# i2c_master_model: IP-XACT component
VLNV IcronTechnologies:IcronTechnologies:i2c_master_model:1.0

## Parameters
addr_width = 8
bus_width = 32

## Bus interfaces (logical=physical port)
default_map: slave AGNISYS:AGNISYS:APB:1.0, memory map i2c_mastermap
  pclk=pclk, presetn=presetn, psel=psel, penable=penable, pwrite=pwrite, pprot=pprot, pstrb=pstrb, pwdata=pwdata, paddr=paddr, pready=pready, prdata=prdata, pslverr=pslverr

## Ports
in pclk
in presetn
in psel
in penable
in pwrite
in pprot[2:0]
in pstrb[(bus_width div 8 )-1:0]
in pwdata[bus_width -1:0]
in paddr[addr_width -1:0]
out pready
out prdata[bus_width -1:0]
out pslverr
out i2c_master_regsversion_major_r[7:0]
out i2c_master_regsversion_minor_r[7:0]
out i2c_master_regsversion_patch_r[7:0]
out i2c_master_regsprescaler_enb
out i2c_master_regsprescaler_prescaler_r[15:0]
out i2c_master_regsfifo_enb
in i2c_master_regsfifo_fifo_af_in
in i2c_master_regsfifo_fifo_af_in_enb
in i2c_master_regsfifo_fifo_ae_in
in i2c_master_regsfifo_fifo_ae_in_enb
in i2c_master_regsfifo_fifo_full_in
in i2c_master_regsfifo_fifo_full_in_enb
in i2c_master_regsfifo_fifo_empty_in
in i2c_master_regsfifo_fifo_empty_in_enb
out i2c_master_regsfifo_fifo_aft_r[7:0]
out i2c_master_regsfifo_fifo_aet_r[7:0]
in i2c_master_regsfifo_fifo_depth_in[7:0]
in i2c_master_regsfifo_fifo_depth_in_enb
out i2c_master_regscontrol_enb
in i2c_master_regscontrol_error_in
in i2c_master_regscontrol_error_in_enb
in i2c_master_regscontrol_clock_stretch_active_in
in i2c_master_regscontrol_clock_stretch_active_in_enb
out i2c_master_regscontrol_force_sda_low_r
out i2c_master_regscontrol_slave_addr_r[6:0]
out i2c_master_regscontrol_read_byte_count_r[7:0]
out i2c_master_regscontrol_clear_r
out i2c_master_regscontrol_opmode_r[1:0]
out i2c_master_regscontrol_clock_stretch_en_r
out i2c_master_regscontrol_go_r
in i2c_master_regscontrol_go_hw_clear
out i2c_master_regswr_data_enb
out i2c_master_regswr_data_wr_data_r[7:0]
out i2c_master_regsregwr_data_wr_data_wr_pulse
in i2c_master_regsrd_data_rd_data_in[7:0]
in i2c_master_regsrd_data_rd_data_in_enb
out i2c_master_regsrd_data_rd_data_rd_pulse

## Address spaces and blocks
i2c_mastermap.i2c_master: base 0x000, range 0x100, width 32

## Registers
Registers are 32-bit, read-only, reset 0x0 unless marked. A register's access mark holds for its fields unless they carry their own. Offsets are from the block's base; lines under a group give offsets from that group; [hi:lo] are bit positions; {n}, {i} and the like mark numbered series; 'fields as' and 'values as' point back to an identical list; <NAME> marks a mode.

## i2c_mastermap.i2c_master — I2C Master
Base 0x00000000
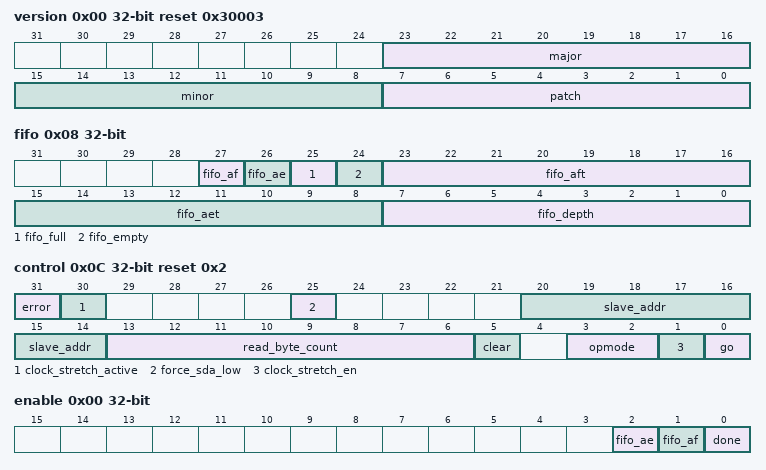
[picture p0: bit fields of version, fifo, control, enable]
0x00 version reset 0x30003
  [23:16] major — Major version
  [15:8] minor — Minor version
  [7:0] patch — Patch version
0x04 prescaler rw — I2C prescaler
  [15:0] prescaler — Prescaler reload value. The value defines the number of clocks in a quarter SCL period. E.g. for a 60MHz clock and a prescaler value of 15 a 1000 KHz SCL will be generated (60e6 * (1 / (15 * 4))).
0x08 fifo access per field — I2C FIFO control and status
  [27] fifo_af ro — FIFO almost full status field. A 1 indicates an almost full or full FIFO. This bit is set when there are between fifo_af_lvl and fifo_depth number of entries in the FIFO.
  [26] fifo_ae ro — FIFO almost empty status field. A 1 indicates an almost empty or empty FIFO. This bit is set when there are between 0 and fifo_ae_lvl number of entries in the FIFO.
  [25] fifo_full ro — FIFO full status field. A 1 indicates a full FIFO.
  [24] fifo_empty ro — FIFO empty status field. A 1 indicates an empty FIFO.
  [23:16] fifo_aft rw — FIFO almost full threshold
  [15:8] fifo_aet rw — FIFO almost empty threshold
  [7:0] fifo_depth ro — FIFO depth (always 1 byte wide)
0x0C control access per field reset 0x2 — I2C control
  [31] error ro — Error status field. A 1 indicates that a transaction error occurred. This could be due to a NAK or a read from the bus when the FIFO is full. This bit is sticky until the clear field is asserted or a new transaction is started.
  [30] clock_stretch_active ro — This status field indicates whether the I2C master is currently being clock stretched (this requires clock_stretch_en to be 1)
  [25] force_sda_low rw — Write a 1 to force the SDA line to 0. Clear this field for normal behaviour.
  [20:14] slave_addr rw — I2C slave address
  [13:6] read_byte_count rw — Write the number of bytes that should be read from the I2C device before ending the transaction. The value should not be bigger than the FIFO depth.
  [5] clear rw — Write a 1 to clear the I2C master. This clears the FIFO and resets the state machine. The clear bit must be asserted for at least 2 PCLK cycles. HW does NOT clear this field so SW should write a 0 to this field after it has written a 1 to clear the I2C master.
  [3:2] opmode rw — Mode of Operation: 2'b00 : I2C Read 2'b01 : I2C Write / SMBus Byte Write / SMBus Block Write 2'b10 : SMBus Byte Read 2'b11 : SMBus Block Read
  [1] clock_stretch_en rw — Clock stretch enable
  [0] go rw — Write a 1 to initiate an I2C transaction. HW will clear this field upon completion and also generates an interrupt. A new transaction should not be attempted until this field returns a 0, indicating it is not busy.
0x10 wr_data wo — I2C write data
  [7:0] wr_data — Byte to write into the I2C master FIFO.
0x14 rd_data — I2C read data
  [7:0] rd_data — Byte to read from the I2C master FIFO.
0x18 irq group — I2C Master Interrupt register group
  0x00 enable rw — Interrupt Enable register - Write 1 to enable, 0 to mask an interrupt
    [2] fifo_ae — FIFO almost empty NOTE: If the FIFO is empty when this interrupt is enabled, it will cause an interrupt right away!
    [1] fifo_af — FIFO almost full
    [0] done — Transfer done
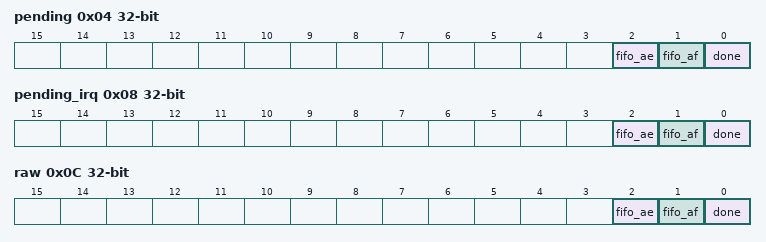
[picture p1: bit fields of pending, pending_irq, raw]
  0x04 pending rw — Pending register - This indicates which events are pending, Write 1 to clear
    [2] fifo_ae write-1-clears — Level-triggered - Active High FIFO almost empty NOTE: If the FIFO is empty, this event is pending and if enabled will cause an interrupt!
    [1] fifo_af write-1-clears — Level-triggered - Active-High FIFO almost full
    [0] done write-1-clears — Edge-triggered - Active High Transfer done
  0x08 pending_irq — Interrupt Pending register - This indicates which pending events are enabled to cause an interrupt
    [2] fifo_ae — Level-triggered - Active High FIFO almost empty
    [1] fifo_af — Level-triggered - Active-High FIFO almost full
    [0] done — Edge-triggered - Active High Transfer done
  0x0C raw — This register contains the registered state of interrupt signals
    [2] fifo_ae — Current state of the FIFO almost empty flag (Active-High)
    [1] fifo_af — Current state of the FIFO almost full flag (Active-High)
    [0] done — Current state of the transfer done flag (Active-High)
